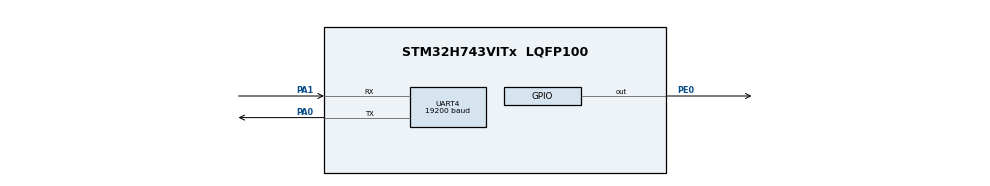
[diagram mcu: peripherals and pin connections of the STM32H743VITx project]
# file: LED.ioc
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CORTEX_M7.CPU_DCache=Disabled
CORTEX_M7.CPU_ICache=Disabled
Mcu.Family=STM32H7
Mcu.Name=STM32H743VITx
Mcu.Package=LQFP100
NVIC.PriorityGroup=NVIC_PRIORITYGROUP_4
NVIC.TIM2_IRQn=true\:0\:0\:false\:false\:true\:true\:true
NVIC.TIM4_IRQn=true\:0\:0\:false\:false\:true\:false\:true
NVIC.TimeBase=TIM4_IRQn
NVIC.TimeBaseIP=TIM4
NVIC.UART4_IRQn=true\:0\:0\:false\:false\:true\:true\:true
PA0.Mode=Asynchronous
PA0.Signal=UART4_TX
PA1.Mode=Asynchronous
PA1.Signal=UART4_RX
PE0.Signal=GPIO_Output
PH0-OSC_IN\ (PH0).Mode=HSE-External-Oscillator
PH0-OSC_IN\ (PH0).Signal=RCC_OSC_IN
PH1-OSC_OUT\ (PH1).Mode=HSE-External-Oscillator
PH1-OSC_OUT\ (PH1).Signal=RCC_OSC_OUT
ProjectManager.HeapSize=0x200
ProjectManager.StackSize=0x400
ProjectManager.TargetToolchain=MDK-ARM V5
RCC.ADCFreq_Value=76000000
RCC.APB1Freq_Value=100000000
RCC.APB2Freq_Value=100000000
RCC.APB3Freq_Value=100000000
RCC.APB4Freq_Value=100000000
RCC.CortexFreq_Value=400000000
RCC.D1PPRE=RCC_APB3_DIV2
RCC.D2PPRE1=RCC_APB1_DIV2
RCC.D2PPRE2=RCC_APB2_DIV2
RCC.D3PPRE=RCC_APB4_DIV2
RCC.DIVM1=1
RCC.DIVM2=1
RCC.DIVN1=100
RCC.DIVN2=19
RCC.HCLKFreq_Value=200000000
RCC.HPRE=RCC_HCLK_DIV2
RCC.HSE_VALUE=8000000
RCC.PLLSourceVirtual=RCC_PLLSOURCE_HSE
RCC.PWR_Regulator_Voltage_Scale=PWR_REGULATOR_VOLTAGE_SCALE1
RCC.SYSCLKFreq_VALUE=400000000
RCC.SYSCLKSource=RCC_SYSCLKSOURCE_PLLCLK
RCC.USBFreq_Value=400000000
TIM2.Period=56465-1
TIM2.Prescaler=2-1
UART4.BaudRate=19200
VP_SYS_VS_tim4.Mode=TIM4
VP_TIM2_VS_ClockSourceINT.Mode=Internal
board=custom

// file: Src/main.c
/* USER CODE BEGIN Header */
/**
  ******************************************************************************
  * @file           : main.c
  * @brief          : Main program body
  ******************************************************************************
  * @attention
  *
  * <h2><center>&copy; Copyright (c) 2019 STMicroelectronics.
  * All rights reserved.</center></h2>
  *
  * This software component is licensed by ST under Ultimate Liberty license
  * SLA0044, the "License"; You may not use this file except in compliance with
  * the License. You may obtain a copy of the License at:
  *                             www.st.com/SLA0044
  *
  ******************************************************************************
  */
/* USER CODE END Header */

#include "main.h"
#include "tim.h"
#include "usart.h"
#include "gpio.h"

/* USER CODE BEGIN Includes */
#include "modbus_host.h"
/* USER CODE END Includes */

/* USER CODE BEGIN PV */
u16 receive[64];
uint8_t buf[6];

/* USER CODE END PV */

void SystemClock_Config(void);

/* USER CODE BEGIN 0 */
u8 RXdata = 0;
/* USER CODE END 0 */

int main(void)
{

  /* MCU Configuration--------------------------------------------------------*/

  /* Reset of all peripherals, Initializes the Flash interface and the Systick. */
  HAL_Init();

  /* Configure the system clock */
  SystemClock_Config();

  /* Initialize all configured peripherals */
  MX_GPIO_Init();
  MX_UART4_Init();
  MX_TIM2_Init();
  /* USER CODE BEGIN 2 */
  HAL_UART_Receive_IT(&huart4, &RXdata, 1);

	buf[0] = 0x00;
	buf[1] = 0x04;
	buf[2] = 0x00;
	buf[3] = 0x05;
	buf[4] = 0x00;
	buf[5] = 0x06;
  /* USER CODE END 2 */

  /* Infinite loop */
  while (1)
  {

    /* USER CODE BEGIN 3 */

	volatile int temp = 0;

	if (MODH_WriteParam_10H(0, 3, buf) == 1)
		temp++;
	else ;      	// 寄存器起始地址 寄存器个数 数据（每个寄存器两个字节，高位在前）

	if (MODH_ReadParam_03H(0, 64) == 1)   // 从0寄存器开始读64个  从站地址0x01
		temp++;
	else ;

//	HAL_Delay(10);

  }
  /* USER CODE END 3 */
}

void SystemClock_Config(void)
{
  RCC_OscInitTypeDef RCC_OscInitStruct = {0};
  RCC_ClkInitTypeDef RCC_ClkInitStruct = {0};
  RCC_PeriphCLKInitTypeDef PeriphClkInitStruct = {0};

  /** Supply configuration update enable
  */
  HAL_PWREx_ConfigSupply(PWR_LDO_SUPPLY);
  /** Configure the main internal regulator output voltage
  */
  __HAL_PWR_VOLTAGESCALING_CONFIG(PWR_REGULATOR_VOLTAGE_SCALE1);

  while(!__HAL_PWR_GET_FLAG(PWR_FLAG_VOSRDY)) {}
  /** Initializes the CPU, AHB and APB busses clocks
  */
  RCC_OscInitStruct.OscillatorType = RCC_OSCILLATORTYPE_HSE;
  RCC_OscInitStruct.HSEState = RCC_HSE_ON;
  RCC_OscInitStruct.PLL.PLLState = RCC_PLL_ON;
  RCC_OscInitStruct.PLL.PLLSource = RCC_PLLSOURCE_HSE;
  RCC_OscInitStruct.PLL.PLLM = 1;
  RCC_OscInitStruct.PLL.PLLN = 100;
  RCC_OscInitStruct.PLL.PLLP = 2;
  RCC_OscInitStruct.PLL.PLLQ = 2;
  RCC_OscInitStruct.PLL.PLLR = 2;
  RCC_OscInitStruct.PLL.PLLRGE = RCC_PLL1VCIRANGE_3;
  RCC_OscInitStruct.PLL.PLLVCOSEL = RCC_PLL1VCOWIDE;
  RCC_OscInitStruct.PLL.PLLFRACN = 0;
  if (HAL_RCC_OscConfig(&RCC_OscInitStruct) != HAL_OK)
  {
    Error_Handler();
  }
  /** Initializes the CPU, AHB and APB busses clocks
  */
  RCC_ClkInitStruct.ClockType = RCC_CLOCKTYPE_HCLK|RCC_CLOCKTYPE_SYSCLK
                              |RCC_CLOCKTYPE_PCLK1|RCC_CLOCKTYPE_PCLK2
                              |RCC_CLOCKTYPE_D3PCLK1|RCC_CLOCKTYPE_D1PCLK1;
  RCC_ClkInitStruct.SYSCLKSource = RCC_SYSCLKSOURCE_PLLCLK;
  RCC_ClkInitStruct.SYSCLKDivider = RCC_SYSCLK_DIV1;
  RCC_ClkInitStruct.AHBCLKDivider = RCC_HCLK_DIV2;
  RCC_ClkInitStruct.APB3CLKDivider = RCC_APB3_DIV2;
  RCC_ClkInitStruct.APB1CLKDivider = RCC_APB1_DIV2;
  RCC_ClkInitStruct.APB2CLKDivider = RCC_APB2_DIV2;
  RCC_ClkInitStruct.APB4CLKDivider = RCC_APB4_DIV2;

  if (HAL_RCC_ClockConfig(&RCC_ClkInitStruct, FLASH_LATENCY_2) != HAL_OK)
  {
    Error_Handler();
  }
  PeriphClkInitStruct.PeriphClockSelection = RCC_PERIPHCLK_UART4;
  PeriphClkInitStruct.Usart234578ClockSelection = RCC_USART234578CLKSOURCE_D2PCLK1;
  if (HAL_RCCEx_PeriphCLKConfig(&PeriphClkInitStruct) != HAL_OK)
  {
    Error_Handler();
  }
}

void HAL_TIM_PeriodElapsedCallback(TIM_HandleTypeDef *htim)
{
  if (htim->Instance == TIM4) {
    HAL_IncTick();
  }
}

void Error_Handler(void)
{
}

/************************ (C) COPYRIGHT STMicroelectronics *****END OF FILE****/
